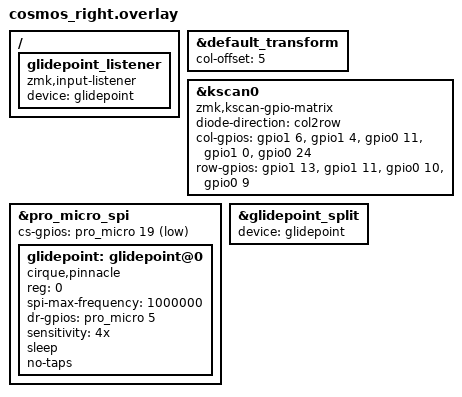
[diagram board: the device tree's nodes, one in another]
#include "cosmos.dtsi"
#include "pmw3610.dtsi"
#include "cosmos-layouts.dtsi"
#include <dt-bindings/zmk/input_transform.h>

&default_transform {
    col-offset = <5>;
};

&kscan0 {
    compatible = "zmk,kscan-gpio-matrix";
    diode-direction = "col2row";

	col-gpios
		= <&gpio1  6 (GPIO_ACTIVE_HIGH)> // col_0_right P1.06
		, <&gpio1  4 (GPIO_ACTIVE_HIGH)> // col_1_right P1.04
		, <&gpio0 11 (GPIO_ACTIVE_HIGH)> // col_2_right P0.11
		, <&gpio1  0 (GPIO_ACTIVE_HIGH)> // col_3_right P1.00
		, <&gpio0 24 (GPIO_ACTIVE_HIGH)> // col_4_right P0.24
		;

	row-gpios
		= <&gpio1 13 (GPIO_ACTIVE_HIGH | GPIO_PULL_DOWN)> // row_0_right P1.13
		, <&gpio1 11 (GPIO_ACTIVE_HIGH | GPIO_PULL_DOWN)> // row_1_right P1.11
		, <&gpio0 10 (GPIO_ACTIVE_HIGH | GPIO_PULL_DOWN)> // row_2_right P0.10
		, <&gpio0  9 (GPIO_ACTIVE_HIGH | GPIO_PULL_DOWN)> // row_3_right P0.09
		;
};

&pro_micro_spi {
    cs-gpios = <&pro_micro 19 GPIO_ACTIVE_LOW>; // pmw3610 is using P0.06 for nCS

    glidepoint: glidepoint@0 {
        compatible = "cirque,pinnacle"; // not using Cirque, but seems like everyone on Github uses this
        reg = <0>;
        spi-max-frequency = <1000000>;
        status = "okay";
        dr-gpios = <&pro_micro 5 (GPIO_ACTIVE_HIGH)>; // what is dr-gpios?

        sensitivity = "4x";
        sleep;
        no-taps;
    };
};

// Overrides for the input-split child node
&glidepoint_split {
    device = <&glidepoint>;
};

/ {
	glidepoint_listener {
        compatible = "zmk,input-listener";
        device = <&glidepoint>;
    };
};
